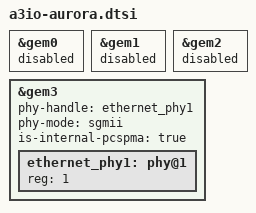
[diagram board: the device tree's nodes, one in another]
#include <dt-bindings/input/input.h>
#include <dt-bindings/gpio/gpio.h>
#include <dt-bindings/pinctrl/pinctrl-zynqmp.h>
#include <dt-bindings/phy/phy.h>

&gem0 {
    status = "disabled";
};

&gem1 {
    status = "disabled";
};

&gem2 {
    status = "disabled";
};

&gem3 {
    status = "okay";
    phy-handle = <&ethernet_phy1>;
    phy-mode = "sgmii";
    is-internal-pcspma = "true";
    ethernet_phy1: phy@1 {
        reg = <1>;
    };
};
